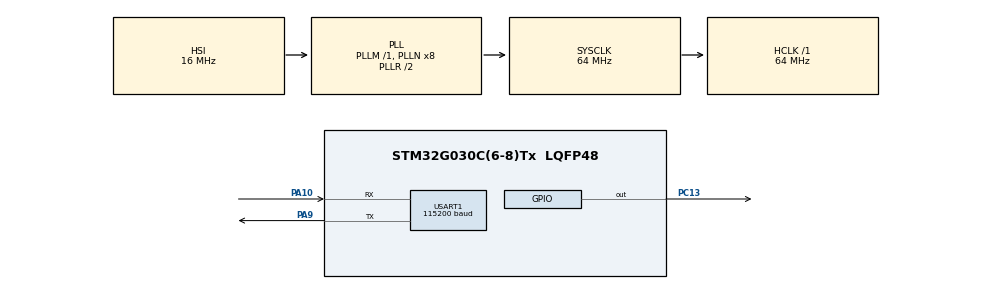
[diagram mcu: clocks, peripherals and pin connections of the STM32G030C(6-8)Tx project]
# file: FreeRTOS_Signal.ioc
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FREERTOS.HEAP_NUMBER=4
FREERTOS.INCLUDE_eTaskGetState=1
FREERTOS.INCLUDE_pcTaskGetTaskName=0
FREERTOS.INCLUDE_uxTaskGetStackHighWaterMark=0
FREERTOS.INCLUDE_uxTaskGetStackHighWaterMark2=0
FREERTOS.INCLUDE_uxTaskPriorityGet=1
FREERTOS.INCLUDE_vTaskCleanUpResources=1
FREERTOS.INCLUDE_vTaskDelay=1
FREERTOS.INCLUDE_vTaskDelayUntil=1
FREERTOS.INCLUDE_vTaskDelete=1
FREERTOS.INCLUDE_vTaskPrioritySet=1
FREERTOS.INCLUDE_vTaskSuspend=1
FREERTOS.INCLUDE_xEventGroupSetBitFromISR=0
FREERTOS.INCLUDE_xQueueGetMutexHolder=0
FREERTOS.INCLUDE_xSemaphoreGetMutexHolder=0
FREERTOS.INCLUDE_xTaskAbortDelay=0
FREERTOS.INCLUDE_xTaskGetCurrentTaskHandle=0
FREERTOS.INCLUDE_xTaskGetHandle=0
FREERTOS.INCLUDE_xTaskGetSchedulerState=1
FREERTOS.INCLUDE_xTaskResumeFromISR=1
FREERTOS.INCLUDE_xTimerPendFunctionCall=0
FREERTOS.MEMORY_ALLOCATION=0
FREERTOS.Tasks01=thread1,0,128,led_thread,Default,NULL,Dynamic,NULL,NULL;thread2,-1,128,usart_thread,Default,NULL,Dynamic,NULL,NULL;thread3,-1,128,signal_gen,Default,NULL,Dynamic,NULL,NULL
FREERTOS.configCHECK_FOR_STACK_OVERFLOW=0
FREERTOS.configENABLE_BACKWARD_COMPATIBILITY=1
FREERTOS.configENABLE_FPU=0
FREERTOS.configGENERATE_RUN_TIME_STATS=0
FREERTOS.configIDLE_SHOULD_YIELD=1
FREERTOS.configMAX_CO_ROUTINE_PRIORITIES=2
FREERTOS.configMAX_PRIORITIES=7
FREERTOS.configMAX_TASK_NAME_LEN=16
FREERTOS.configMINIMAL_STACK_SIZE=128
FREERTOS.configQUEUE_REGISTRY_SIZE=8
FREERTOS.configRECORD_STACK_HIGH_ADDRESS=0
FREERTOS.configTICK_RATE_HZ=1000
FREERTOS.configTIMER_QUEUE_LENGTH=10
FREERTOS.configTIMER_TASK_PRIORITY=2
FREERTOS.configTIMER_TASK_STACK_DEPTH=256
FREERTOS.configTOTAL_HEAP_SIZE=5120
FREERTOS.configUSE_APPLICATION_TASK_TAG=0
FREERTOS.configUSE_COUNTING_SEMAPHORES=1
FREERTOS.configUSE_CO_ROUTINES=0
FREERTOS.configUSE_DAEMON_TASK_STARTUP_HOOK=0
FREERTOS.configUSE_IDLE_HOOK=0
FREERTOS.configUSE_MALLOC_FAILED_HOOK=0
FREERTOS.configUSE_MUTEXES=1
FREERTOS.configUSE_NEWLIB_REENTRANT=0
FREERTOS.configUSE_POSIX_ERRNO=0
FREERTOS.configUSE_PREEMPTION=1
FREERTOS.configUSE_RECURSIVE_MUTEXES=1
FREERTOS.configUSE_STATS_FORMATTING_FUNCTIONS=0
FREERTOS.configUSE_TASK_NOTIFICATIONS=1
FREERTOS.configUSE_TICKLESS_IDLE=0
FREERTOS.configUSE_TICK_HOOK=0
FREERTOS.configUSE_TIMERS=1
FREERTOS.configUSE_TRACE_FACILITY=1
FREERTOS.copyHeapFile=1
Mcu.Family=STM32G0
Mcu.Name=STM32G030C(6-8)Tx
Mcu.Package=LQFP48
NVIC.TIM1_BRK_UP_TRG_COM_IRQn=true\:3\:0\:false\:false\:true\:false\:true\:true\:true
NVIC.TimeBase=TIM1_BRK_UP_TRG_COM_IRQn
NVIC.TimeBaseIP=TIM1
PA10.Mode=Asynchronous
PA10.Signal=USART1_RX
PA13.Mode=Serial_Wire
PA13.Signal=SYS_SWDIO
PA14-BOOT0.Mode=Serial_Wire
PA14-BOOT0.Signal=SYS_SWCLK
PA9.Mode=Asynchronous
PA9.Signal=USART1_TX
PC13.Signal=GPIO_Output
ProjectManager.HeapSize=0x200
ProjectManager.StackSize=0x400
ProjectManager.TargetToolchain=MDK-ARM V5.32
RCC.ADCFreq_Value=64000000
RCC.AHBFreq_Value=64000000
RCC.CortexFreq_Value=64000000
RCC.EXTERNAL_CLOCK_VALUE=12288000
RCC.FLatency=FLASH_LATENCY_2
RCC.HCLKFreq_Value=64000000
RCC.HSE_VALUE=8000000
RCC.HSI_VALUE=16000000
RCC.LSE_VALUE=32768
RCC.SYSCLKFreq_VALUE=64000000
RCC.SYSCLKSource=RCC_SYSCLKSOURCE_PLLCLK
RCC.VCOOutputFreq_Value=128000000
USART1.AutoBaudRateEnableParam=UART_ADVFEATURE_AUTOBAUDRATE_DISABLE
USART1.BaudRate=115200
USART1.ClockPrescaler=PRESCALER_DIV1
USART1.DMADisableonRxErrorParam=ADVFEATURE_DMA_ENABLEONRXERROR
USART1.DataInvertParam=ADVFEATURE_DATAINV_DISABLE
USART1.FIFOMode=FIFOMODE_DISABLE
USART1.MSBFirstParam=ADVFEATURE_MSBFIRST_DISABLE
USART1.Mode=MODE_TX_RX
USART1.OneBitSampling=UART_ONE_BIT_SAMPLE_DISABLE
USART1.OverSampling=UART_OVERSAMPLING_16
USART1.OverrunDisableParam=ADVFEATURE_OVERRUN_ENABLE
USART1.Parity=PARITY_NONE
USART1.RXFIFOThreshold=RXFIFO_THRESHOLD_1EIGHTHFULL
USART1.RxPinLevelInvertParam=ADVFEATURE_RXINV_DISABLE
USART1.StopBits=STOPBITS_1
USART1.SwapParam=ADVFEATURE_SWAP_DISABLE
USART1.TXFIFOThreshold=TXFIFO_THRESHOLD_1EIGHTHFULL
USART1.TxPinLevelInvertParam=ADVFEATURE_TXINV_DISABLE
USART1.VirtualMode-Asynchronous=VM_ASYNC
USART1.WordLength=WORDLENGTH_8B
VP_FREERTOS_VS_CMSIS_V1.Mode=CMSIS_V1
VP_SYS_VS_tim1.Mode=TIM1
board=custom

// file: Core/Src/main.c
/* USER CODE BEGIN Header */
/**
  ******************************************************************************
  * @file           : main.c
  * @brief          : Main program body
  ******************************************************************************
  * @attention
  *
  * <h2><center>&copy; Copyright (c) 2021 STMicroelectronics.
  * All rights reserved.</center></h2>
  *
  * This software component is licensed by ST under Ultimate Liberty license
  * SLA0044, the "License"; You may not use this file except in compliance with
  * the License. You may obtain a copy of the License at:
  *                             www.st.com/SLA0044
  *
  ******************************************************************************
  */
/* USER CODE END Header */
#include "main.h"
#include "cmsis_os.h"
#include "usart.h"
#include "gpio.h"

void SystemClock_Config(void);
void MX_FREERTOS_Init(void);

int main(void)
{

  /* MCU Configuration--------------------------------------------------------*/

  /* Reset of all peripherals, Initializes the Flash interface and the Systick. */
  HAL_Init();

  /* Configure the system clock */
  SystemClock_Config();

  /* Initialize all configured peripherals */
  MX_GPIO_Init();
  MX_USART1_UART_Init();

  /* Call init function for freertos objects (in freertos.c) */
  MX_FREERTOS_Init();
  /* Start scheduler */
  osKernelStart();

  /* We should never get here as control is now taken by the scheduler */
  /* Infinite loop */
  while (1)
  {

  }
}

void SystemClock_Config(void)
{
  RCC_OscInitTypeDef RCC_OscInitStruct = {0};
  RCC_ClkInitTypeDef RCC_ClkInitStruct = {0};
  RCC_PeriphCLKInitTypeDef PeriphClkInit = {0};

  /** Configure the main internal regulator output voltage
  */
  HAL_PWREx_ControlVoltageScaling(PWR_REGULATOR_VOLTAGE_SCALE1);
  /** Initializes the RCC Oscillators according to the specified parameters
  * in the RCC_OscInitTypeDef structure.
  */
  RCC_OscInitStruct.OscillatorType = RCC_OSCILLATORTYPE_HSI;
  RCC_OscInitStruct.HSIState = RCC_HSI_ON;
  RCC_OscInitStruct.HSIDiv = RCC_HSI_DIV1;
  RCC_OscInitStruct.HSICalibrationValue = RCC_HSICALIBRATION_DEFAULT;
  RCC_OscInitStruct.PLL.PLLState = RCC_PLL_ON;
  RCC_OscInitStruct.PLL.PLLSource = RCC_PLLSOURCE_HSI;
  RCC_OscInitStruct.PLL.PLLM = RCC_PLLM_DIV1;
  RCC_OscInitStruct.PLL.PLLN = 8;
  RCC_OscInitStruct.PLL.PLLP = RCC_PLLP_DIV2;
  RCC_OscInitStruct.PLL.PLLR = RCC_PLLR_DIV2;
  if (HAL_RCC_OscConfig(&RCC_OscInitStruct) != HAL_OK)
  {
    Error_Handler();
  }
  /** Initializes the CPU, AHB and APB buses clocks
  */
  RCC_ClkInitStruct.ClockType = RCC_CLOCKTYPE_HCLK|RCC_CLOCKTYPE_SYSCLK
                              |RCC_CLOCKTYPE_PCLK1;
  RCC_ClkInitStruct.SYSCLKSource = RCC_SYSCLKSOURCE_PLLCLK;
  RCC_ClkInitStruct.AHBCLKDivider = RCC_SYSCLK_DIV1;
  RCC_ClkInitStruct.APB1CLKDivider = RCC_HCLK_DIV1;

  if (HAL_RCC_ClockConfig(&RCC_ClkInitStruct, FLASH_LATENCY_2) != HAL_OK)
  {
    Error_Handler();
  }
  /** Initializes the peripherals clocks
  */
  PeriphClkInit.PeriphClockSelection = RCC_PERIPHCLK_USART1;
  PeriphClkInit.Usart1ClockSelection = RCC_USART1CLKSOURCE_PCLK1;
  if (HAL_RCCEx_PeriphCLKConfig(&PeriphClkInit) != HAL_OK)
  {
    Error_Handler();
  }
}

void HAL_TIM_PeriodElapsedCallback(TIM_HandleTypeDef *htim)
{
  if (htim->Instance == TIM1) {
    HAL_IncTick();
  }
}

void Error_Handler(void)
{
  __disable_irq();
  while (1)
  {
  }
}

/************************ (C) COPYRIGHT STMicroelectronics *****END OF FILE****/

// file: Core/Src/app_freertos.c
/* USER CODE BEGIN Header */
/**
  ******************************************************************************
  * File Name          : app_freertos.c
  * Description        : Code for freertos applications
  ******************************************************************************
  * @attention
  *
  * <h2><center>&copy; Copyright (c) 2021 STMicroelectronics.
  * All rights reserved.</center></h2>
  *
  * This software component is licensed by ST under Ultimate Liberty license
  * SLA0044, the "License"; You may not use this file except in compliance with
  * the License. You may obtain a copy of the License at:
  *                             www.st.com/SLA0044
  *
  ******************************************************************************
  */
/* USER CODE END Header */

#include "FreeRTOS.h"
#include "task.h"
#include "main.h"
#include "cmsis_os.h"

/* USER CODE BEGIN Includes */
#include "usart.h"

/* USER CODE END Includes */

/* USER CODE BEGIN PD */
#define BIT_0  ( 1 << 0 )
#define BIT_1  ( 1 << 1 )

/* USER CODE END PD */

osThreadId thread1Handle;
osThreadId thread2Handle;
osThreadId thread3Handle;

void led_thread(void const * argument);
void usart_thread(void const * argument);
void signal_gen(void const * argument);

void MX_FREERTOS_Init(void); /* (MISRA C 2004 rule 8.1) */

void MX_FREERTOS_Init(void) {

  /* Create the thread(s) */
  /* definition and creation of thread1 */
  osThreadDef(thread1, led_thread, osPriorityNormal, 0, 128);
  thread1Handle = osThreadCreate(osThread(thread1), NULL);

  /* definition and creation of thread2 */
  osThreadDef(thread2, usart_thread, osPriorityBelowNormal, 0, 128);
  thread2Handle = osThreadCreate(osThread(thread2), NULL);

  /* definition and creation of thread3 */
  osThreadDef(thread3, signal_gen, osPriorityBelowNormal, 0, 128);
  thread3Handle = osThreadCreate(osThread(thread3), NULL);

}

void led_thread(void const * argument)
{
  /* USER CODE BEGIN led_thread */
	(void) argument;
  osEvent event;
  /* Infinite loop */
  for(;;)
  {
    event = osSignalWait( BIT_0, osWaitForever);
    if(event.value.signals == BIT_0) {
				HAL_GPIO_TogglePin(GPIOC, GPIO_PIN_13);
		}
  }
  /* USER CODE END led_thread */
}

void usart_thread(void const * argument)
{
  /* USER CODE BEGIN usart_thread */
  /* USER CODE BEGIN usart_thread */
	(void) argument;
  osEvent event;
	char tx[] = "FreeRTOS usart_thread signal test...\r\n";
  /* Infinite loop */
  for(;;)
  {
    event = osSignalWait( BIT_1, osWaitForever);
    if(event.value.signals == BIT_1) {
				HAL_UART_Transmit(&huart1, (uint8_t *)tx, sizeof(tx), 0xffff);
		}
  }
  /* USER CODE END usart_thread */
}

void signal_gen(void const * argument)
{
  /* USER CODE BEGIN signal_gen */
	(void) argument;
  /* Infinite loop */
  for(;;)
  {
    osSignalSet(thread1Handle, BIT_0 );
    osDelay(500);
    osSignalSet(thread2Handle, BIT_1 );
    osDelay(500);
  }
  /* USER CODE END signal_gen */
}

/************************ (C) COPYRIGHT STMicroelectronics *****END OF FILE****/
